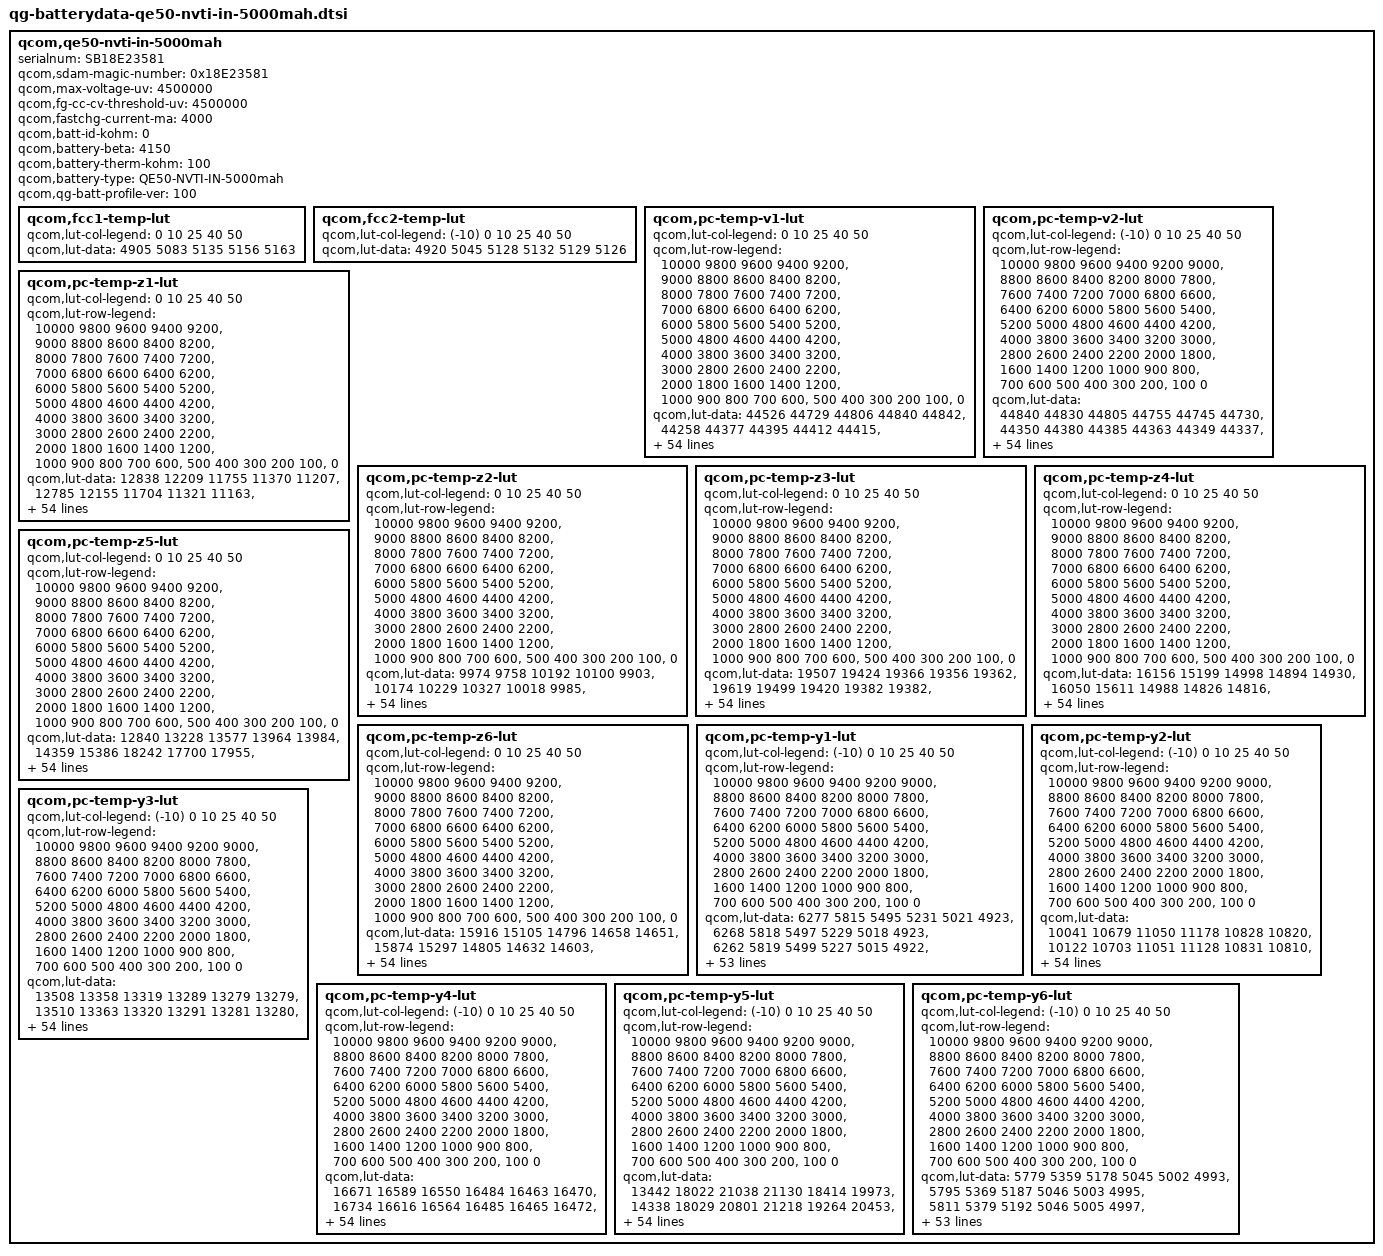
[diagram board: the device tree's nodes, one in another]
/* Copyright (c) 2018, The Linux Foundation. All rights reserved.
 *
 * This program is free software; you can redistribute it and/or modify
 * it under the terms of the GNU General Public License version 2 and
 * only version 2 as published by the Free Software Foundation.
 *
 * This program is distributed in the hope that it will be useful,
 * but WITHOUT ANY WARRANTY; without even the implied warranty of
 * MERCHANTABILITY or FITNESS FOR A PARTICULAR PURPOSE.  See the
 * GNU General Public License for more details.
 */

qcom,qe50-nvti-in-5000mah {
    /* 7091166_Huaqin_QN6982A_5000mAH_PM7250B_averaged_MasterSlave_Apr16th2024 */
    serialnum = "SB18E23581";
    qcom,sdam-magic-number = <0x18E23581>;
    qcom,max-voltage-uv = <4500000>;
    qcom,fg-cc-cv-threshold-uv = <4500000>;
    qcom,fastchg-current-ma = <4000>;
    qcom,batt-id-kohm = <0>;
    qcom,battery-beta = <4150>;
    qcom,battery-therm-kohm = <100>;
    qcom,battery-type = "QE50-NVTI-IN-5000mah";
    qcom,qg-batt-profile-ver = <100>;

	qcom,fcc1-temp-lut {
		qcom,lut-col-legend = <0 10 25 40 50>;
		qcom,lut-data = <4905 5083 5135 5156 5163>;
	};

	qcom,fcc2-temp-lut {
		qcom,lut-col-legend = <(-10) 0 10 25 40 50>;
		qcom,lut-data = <4920 5045 5128 5132 5129 5126>;
	};

	qcom,pc-temp-v1-lut {
		qcom,lut-col-legend = <0 10 25 40 50>;
		qcom,lut-row-legend = <10000 9800 9600 9400 9200>,
			<9000 8800 8600 8400 8200>,
			<8000 7800 7600 7400 7200>,
			<7000 6800 6600 6400 6200>,
			<6000 5800 5600 5400 5200>,
			<5000 4800 4600 4400 4200>,
			<4000 3800 3600 3400 3200>,
			<3000 2800 2600 2400 2200>,
			<2000 1800 1600 1400 1200>,
			<1000 900 800 700 600>,
			<500 400 300 200 100>,
			<0>;
		qcom,lut-data = <44526 44729 44806 44840 44842>,
			<44258 44377 44395 44412 44415>,
			<44018 44137 44140 44133 44132>,
			<43808 43932 43925 43917 43909>,
			<43598 43711 43709 43707 43695>,
			<43373 43489 43489 43487 43478>,
			<43140 43260 43265 43262 43260>,
			<42902 43019 43030 43029 43030>,
			<42657 42772 42785 42787 42789>,
			<42412 42524 42538 42542 42545>,
			<42173 42273 42288 42295 42297>,
			<41938 42028 42040 42049 42050>,
			<41707 41785 41797 41807 41808>,
			<41480 41548 41558 41569 41569>,
			<41260 41321 41327 41337 41337>,
			<41047 41101 41102 41111 41110>,
			<40842 40889 40886 40891 40888>,
			<40644 40683 40678 40682 40677>,
			<40454 40487 40481 40481 40474>,
			<40271 40303 40296 40294 40285>,
			<40095 40127 40126 40126 40115>,
			<39926 39938 39938 39936 39927>,
			<39753 39740 39710 39665 39664>,
			<39563 39530 39476 39385 39389>,
			<39367 39274 39264 39199 39206>,
			<39168 39027 39067 39059 39070>,
			<38952 38885 38921 38933 38943>,
			<38784 38795 38818 38817 38815>,
			<38690 38712 38727 38710 38699>,
			<38620 38623 38631 38608 38598>,
			<38555 38539 38539 38514 38509>,
			<38493 38461 38455 38430 38427>,
			<38436 38388 38377 38356 38351>,
			<38382 38322 38306 38287 38278>,
			<38332 38266 38244 38220 38207>,
			<38287 38214 38187 38155 38137>,
			<38250 38170 38130 38088 38066>,
			<38211 38131 38075 38023 37996>,
			<38164 38079 38008 37944 37911>,
			<38108 38002 37923 37839 37790>,
			<38034 37906 37822 37718 37652>,
			<37919 37789 37708 37602 37528>,
			<37783 37645 37572 37481 37404>,
			<37632 37477 37407 37317 37235>,
			<37473 37307 37243 37166 37087>,
			<37290 37174 37127 37072 37007>,
			<37222 37128 37085 37038 36981>,
			<37171 37093 37056 37014 36958>,
			<37134 37070 37030 36989 36932>,
			<37096 37036 36994 36951 36886>,
			<37051 36911 36835 36753 36664>,
			<36980 36513 36414 36335 36245>,
			<36715 35913 35829 35762 35671>,
			<36163 35068 35026 34976 34885>,
			<35205 33680 33776 33761 33666>,
			<30000 30000 30000 30000 30000>;
	};

	qcom,pc-temp-v2-lut {
		qcom,lut-col-legend = <(-10) 0 10 25 40 50>;
		qcom,lut-row-legend = <10000 9800 9600 9400 9200 9000>,
			<8800 8600 8400 8200 8000 7800>,
			<7600 7400 7200 7000 6800 6600>,
			<6400 6200 6000 5800 5600 5400>,
			<5200 5000 4800 4600 4400 4200>,
			<4000 3800 3600 3400 3200 3000>,
			<2800 2600 2400 2200 2000 1800>,
			<1600 1400 1200 1000 900 800>,
			<700 600 500 400 300 200>,
			<100 0>;
		qcom,lut-data = <44840 44830 44805 44755 44745 44730>,
			<44350 44380 44385 44363 44349 44337>,
			<43941 44005 44031 44028 44011 44001>,
			<43639 43725 43760 43764 43746 43736>,
			<43416 43516 43551 43553 43537 43525>,
			<43206 43310 43340 43341 43325 43314>,
			<42974 43083 43110 43111 43096 43085>,
			<42738 42851 42874 42874 42861 42851>,
			<42502 42612 42630 42632 42619 42612>,
			<42263 42364 42379 42384 42371 42366>,
			<42026 42117 42130 42136 42123 42121>,
			<41796 41871 41883 41890 41876 41876>,
			<41570 41627 41639 41646 41632 41633>,
			<41345 41393 41399 41407 41396 41396>,
			<41127 41167 41164 41174 41166 41163>,
			<40902 40953 40937 40948 40942 40938>,
			<40650 40761 40718 40729 40722 40719>,
			<40379 40566 40509 40519 40511 40509>,
			<40113 40333 40323 40320 40313 40308>,
			<39853 40064 40140 40127 40123 40114>,
			<39604 39803 39917 39934 39940 39933>,
			<39374 39552 39641 39741 39770 39769>,
			<39161 39317 39381 39532 39577 39583>,
			<38959 39111 39155 39269 39310 39319>,
			<38753 38925 38952 39010 39038 39047>,
			<38567 38757 38782 38830 38855 38865>,
			<38428 38605 38635 38691 38717 38729>,
			<38316 38465 38502 38569 38595 38607>,
			<38224 38329 38381 38457 38482 38489>,
			<38146 38198 38271 38355 38379 38382>,
			<38078 38096 38171 38259 38288 38288>,
			<38012 38017 38079 38169 38205 38203>,
			<37950 37949 37998 38089 38128 38127>,
			<37888 37890 37926 38018 38060 38063>,
			<37827 37839 37861 37948 37991 37995>,
			<37766 37786 37806 37875 37914 37908>,
			<37702 37729 37757 37801 37830 37808>,
			<37636 37669 37699 37721 37736 37702>,
			<37566 37602 37635 37634 37626 37588>,
			<37492 37528 37558 37543 37516 37476>,
			<37414 37440 37456 37448 37422 37380>,
			<37327 37330 37333 37344 37324 37281>,
			<37228 37206 37188 37222 37216 37171>,
			<37123 37064 37021 37079 37063 37011>,
			<37012 36903 36841 36935 36930 36882>,
			<36917 36761 36721 36861 36869 36820>,
			<36869 36705 36678 36845 36857 36807>,
			<36822 36659 36635 36829 36843 36793>,
			<36776 36619 36576 36803 36820 36769>,
			<36726 36569 36482 36738 36765 36710>,
			<36663 36476 36254 36510 36551 36475>,
			<36582 36281 35728 36017 36073 35983>,
			<36481 35866 34900 35343 35433 35336>,
			<36172 35055 33898 34407 34534 34428>,
			<35860 34221 32625 32974 33234 33115>,
			<35541 33188 28873 28521 28685 28727>;
	};

	qcom,pc-temp-z1-lut {
		qcom,lut-col-legend = <0 10 25 40 50>;
		qcom,lut-row-legend = <10000 9800 9600 9400 9200>,
			<9000 8800 8600 8400 8200>,
			<8000 7800 7600 7400 7200>,
			<7000 6800 6600 6400 6200>,
			<6000 5800 5600 5400 5200>,
			<5000 4800 4600 4400 4200>,
			<4000 3800 3600 3400 3200>,
			<3000 2800 2600 2400 2200>,
			<2000 1800 1600 1400 1200>,
			<1000 900 800 700 600>,
			<500 400 300 200 100>,
			<0>;
		qcom,lut-data = <12838 12209 11755 11370 11207>,
			<12785 12155 11704 11321 11163>,
			<12758 12145 11674 11306 11152>,
			<12748 12139 11661 11294 11144>,
			<12742 12124 11647 11283 11137>,
			<12733 12099 11628 11274 11130>,
			<12719 12076 11611 11265 11124>,
			<12707 12055 11600 11257 11119>,
			<12689 12037 11592 11250 11116>,
			<12666 12022 11584 11245 11113>,
			<12638 12006 11578 11242 11112>,
			<12602 11998 11572 11240 11110>,
			<12573 11987 11567 11239 11109>,
			<12549 11979 11562 11238 11108>,
			<12530 11976 11561 11237 11107>,
			<12515 11971 11561 11236 11107>,
			<12504 11970 11561 11235 11106>,
			<12496 11971 11560 11235 11107>,
			<12489 11972 11560 11236 11108>,
			<12484 11971 11562 11236 11108>,
			<12489 11969 11566 11236 11108>,
			<12511 11969 11569 11236 11108>,
			<12529 11969 11568 11237 11108>,
			<12538 11970 11567 11237 11109>,
			<12545 11980 11569 11238 11110>,
			<12545 11995 11575 11240 11111>,
			<12534 12001 11579 11243 11114>,
			<12525 12003 11582 11246 11115>,
			<12528 12006 11586 11250 11117>,
			<12538 12011 11591 11253 11120>,
			<12543 12015 11599 11256 11122>,
			<12555 12017 11602 11260 11125>,
			<12565 12016 11604 11263 11127>,
			<12567 12017 11607 11267 11130>,
			<12572 12024 11614 11272 11134>,
			<12575 12033 11623 11277 11139>,
			<12577 12041 11630 11283 11143>,
			<12580 12050 11636 11288 11147>,
			<12595 12060 11644 11293 11151>,
			<12628 12072 11656 11299 11156>,
			<12649 12083 11667 11304 11161>,
			<12668 12086 11673 11310 11165>,
			<12680 12090 11679 11315 11168>,
			<12708 12109 11685 11320 11171>,
			<12713 12136 11698 11326 11175>,
			<12749 12133 11709 11329 11177>,
			<12767 12130 11708 11329 11178>,
			<12752 12156 11711 11330 11179>,
			<12730 12128 11715 11334 11182>,
			<12778 12145 11719 11339 11187>,
			<12745 12153 11741 11347 11192>,
			<12769 12183 11749 11357 11202>,
			<12781 12192 11773 11372 11215>,
			<12801 12227 11798 11395 11238>,
			<12801 12227 11798 11395 11238>,
			<12801 12227 11798 11395 11238>;
	};

	qcom,pc-temp-z2-lut {
		qcom,lut-col-legend = <0 10 25 40 50>;
		qcom,lut-row-legend = <10000 9800 9600 9400 9200>,
			<9000 8800 8600 8400 8200>,
			<8000 7800 7600 7400 7200>,
			<7000 6800 6600 6400 6200>,
			<6000 5800 5600 5400 5200>,
			<5000 4800 4600 4400 4200>,
			<4000 3800 3600 3400 3200>,
			<3000 2800 2600 2400 2200>,
			<2000 1800 1600 1400 1200>,
			<1000 900 800 700 600>,
			<500 400 300 200 100>,
			<0>;
		qcom,lut-data = <9974 9758 10192 10100 9903>,
			<10174 10229 10327 10018 9985>,
			<10222 10287 10358 10182 10024>,
			<10208 10337 10345 10176 10136>,
			<10189 10330 10339 10170 10215>,
			<10170 10289 10340 10167 10199>,
			<10148 10258 10340 10163 10165>,
			<10130 10240 10304 10155 10140>,
			<10116 10226 10220 10139 10119>,
			<10103 10212 10193 10122 10101>,
			<10093 10198 10193 10093 10087>,
			<10083 10196 10194 10064 10074>,
			<10080 10210 10198 10058 10053>,
			<10082 10224 10204 10060 10026>,
			<10085 10229 10206 10065 10019>,
			<10093 10233 10205 10075 10037>,
			<10110 10239 10205 10081 10054>,
			<10128 10249 10217 10075 10051>,
			<10142 10262 10230 10064 10040>,
			<10156 10273 10230 10062 10040>,
			<10171 10285 10223 10070 10046>,
			<10186 10302 10223 10084 10058>,
			<10202 10330 10281 10292 10209>,
			<10225 10347 10343 10551 10411>,
			<10249 10348 10319 10496 10386>,
			<10261 10346 10246 10218 10198>,
			<10269 10337 10222 10107 10124>,
			<10273 10315 10237 10253 10370>,
			<10274 10303 10253 10397 10624>,
			<10275 10305 10260 10365 10531>,
			<10276 10307 10265 10258 10245>,
			<10280 10308 10267 10171 10081>,
			<10284 10312 10267 10094 9996>,
			<10289 10317 10266 10048 9957>,
			<10295 10331 10257 10038 9962>,
			<10302 10346 10247 10035 9977>,
			<10311 10354 10251 10047 9999>,
			<10318 10358 10277 10086 10042>,
			<10321 10366 10302 10122 10087>,
			<10325 10382 10324 10146 10136>,
			<10326 10395 10340 10165 10176>,
			<10326 10391 10342 10181 10185>,
			<10327 10382 10342 10195 10185>,
			<10337 10382 10337 10198 10182>,
			<10291 10412 10344 10201 10177>,
			<10474 10464 10354 10194 10158>,
			<10463 10457 10350 10195 10147>,
			<10402 10456 10325 10190 10146>,
			<10203 10670 10326 10203 10153>,
			<10016 10860 10348 10252 10212>,
			<10068 10873 10356 10223 10181>,
			<10048 10534 10340 10146 10044>,
			<9939 10376 10312 10087 10000>,
			<9828 10286 10269 10054 9963>,
			<9828 10286 10269 10054 9963>,
			<9828 10286 10269 10054 9963>;
	};

	qcom,pc-temp-z3-lut {
		qcom,lut-col-legend = <0 10 25 40 50>;
		qcom,lut-row-legend = <10000 9800 9600 9400 9200>,
			<9000 8800 8600 8400 8200>,
			<8000 7800 7600 7400 7200>,
			<7000 6800 6600 6400 6200>,
			<6000 5800 5600 5400 5200>,
			<5000 4800 4600 4400 4200>,
			<4000 3800 3600 3400 3200>,
			<3000 2800 2600 2400 2200>,
			<2000 1800 1600 1400 1200>,
			<1000 900 800 700 600>,
			<500 400 300 200 100>,
			<0>;
		qcom,lut-data = <19507 19424 19366 19356 19362>,
			<19619 19499 19420 19382 19382>,
			<19661 19518 19436 19407 19402>,
			<19673 19527 19442 19407 19406>,
			<19678 19531 19443 19408 19408>,
			<19678 19534 19441 19413 19410>,
			<19677 19535 19440 19419 19412>,
			<19675 19533 19440 19420 19412>,
			<19673 19529 19440 19418 19411>,
			<19669 19526 19440 19416 19409>,
			<19663 19523 19437 19413 19408>,
			<19653 19519 19434 19409 19405>,
			<19645 19513 19431 19405 19403>,
			<19639 19507 19428 19401 19399>,
			<19632 19501 19426 19398 19396>,
			<19625 19495 19424 19396 19393>,
			<19616 19491 19422 19394 19391>,
			<19608 19489 19419 19391 19387>,
			<19602 19487 19415 19388 19384>,
			<19597 19483 19412 19384 19380>,
			<19592 19480 19407 19378 19374>,
			<19586 19480 19406 19375 19370>,
			<19584 19484 19413 19385 19375>,
			<19587 19487 19421 19397 19382>,
			<19594 19489 19418 19393 19378>,
			<19597 19490 19409 19373 19362>,
			<19599 19489 19406 19365 19356>,
			<19599 19484 19407 19390 19390>,
			<19597 19482 19410 19414 19427>,
			<19591 19483 19415 19416 19426>,
			<19586 19484 19423 19415 19416>,
			<19583 19486 19424 19412 19407>,
			<19580 19488 19423 19404 19399>,
			<19579 19488 19422 19395 19390>,
			<19577 19487 19418 19387 19382>,
			<19576 19485 19414 19380 19373>,
			<19574 19482 19410 19373 19364>,
			<19571 19478 19406 19367 19354>,
			<19567 19474 19403 19364 19350>,
			<19561 19470 19401 19366 19352>,
			<19555 19466 19399 19368 19355>,
			<19551 19463 19395 19367 19357>,
			<19545 19460 19391 19365 19360>,
			<19536 19457 19390 19366 19362>,
			<19425 19447 19387 19365 19361>,
			<19482 19428 19378 19358 19355>,
			<19475 19427 19377 19356 19352>,
			<19423 19424 19371 19346 19341>,
			<19315 19349 19366 19344 19334>,
			<19269 19321 19365 19334 19325>,
			<19268 19319 19366 19347 19332>,
			<19265 19377 19378 19359 19349>,
			<19271 19429 19381 19360 19350>,
			<19336 19447 19382 19362 19352>,
			<19336 19447 19382 19362 19352>,
			<19336 19447 19382 19362 19352>;
	};

	qcom,pc-temp-z4-lut {
		qcom,lut-col-legend = <0 10 25 40 50>;
		qcom,lut-row-legend = <10000 9800 9600 9400 9200>,
			<9000 8800 8600 8400 8200>,
			<8000 7800 7600 7400 7200>,
			<7000 6800 6600 6400 6200>,
			<6000 5800 5600 5400 5200>,
			<5000 4800 4600 4400 4200>,
			<4000 3800 3600 3400 3200>,
			<3000 2800 2600 2400 2200>,
			<2000 1800 1600 1400 1200>,
			<1000 900 800 700 600>,
			<500 400 300 200 100>,
			<0>;
		qcom,lut-data = <16156 15199 14998 14894 14930>,
			<16050 15611 14988 14826 14816>,
			<15891 15434 15074 14924 14904>,
			<15644 15185 14966 14871 14858>,
			<15412 15060 14883 14819 14812>,
			<15267 14975 14838 14792 14789>,
			<15154 14912 14804 14770 14771>,
			<15066 14864 14778 14750 14755>,
			<14993 14825 14757 14732 14741>,
			<14935 14795 14741 14723 14734>,
			<14889 14770 14726 14720 14732>,
			<14852 14751 14716 14718 14731>,
			<14821 14736 14710 14715 14729>,
			<14794 14725 14706 14711 14726>,
			<14772 14721 14703 14708 14724>,
			<14757 14718 14699 14704 14721>,
			<14744 14715 14696 14700 14718>,
			<14737 14711 14694 14697 14715>,
			<14733 14708 14691 14694 14713>,
			<14730 14704 14688 14689 14708>,
			<14728 14700 14684 14680 14697>,
			<14725 14700 14683 14675 14690>,
			<14724 14708 14704 14712 14728>,
			<14730 14721 14736 14768 14786>,
			<14745 14767 14769 14794 14807>,
			<14767 14821 14805 14811 14818>,
			<14812 14825 14813 14814 14820>,
			<14841 14804 14793 14774 14769>,
			<14836 14783 14768 14728 14715>,
			<14821 14766 14748 14714 14708>,
			<14808 14752 14729 14706 14706>,
			<14797 14741 14717 14700 14702>,
			<14787 14732 14710 14695 14697>,
			<14778 14727 14704 14690 14691>,
			<14770 14725 14700 14685 14685>,
			<14762 14722 14697 14679 14679>,
			<14755 14719 14694 14675 14675>,
			<14746 14715 14692 14672 14671>,
			<14735 14710 14691 14671 14670>,
			<14721 14705 14691 14680 14684>,
			<14711 14699 14692 14691 14700>,
			<14704 14691 14689 14689 14698>,
			<14696 14681 14680 14681 14689>,
			<14681 14671 14674 14684 14696>,
			<14749 14657 14663 14681 14697>,
			<14668 14645 14644 14654 14662>,
			<14676 14640 14640 14648 14652>,
			<14735 14637 14635 14643 14645>,
			<14852 14713 14627 14628 14631>,
			<14898 14740 14618 14618 14618>,
			<14895 14741 14623 14635 14654>,
			<14892 14688 14633 14658 14682>,
			<14896 14643 14637 14668 14693>,
			<14865 14654 14644 14674 14699>,
			<14865 14654 14644 14674 14699>,
			<14865 14654 14644 14674 14699>;
	};

	qcom,pc-temp-z5-lut {
		qcom,lut-col-legend = <0 10 25 40 50>;
		qcom,lut-row-legend = <10000 9800 9600 9400 9200>,
			<9000 8800 8600 8400 8200>,
			<8000 7800 7600 7400 7200>,
			<7000 6800 6600 6400 6200>,
			<6000 5800 5600 5400 5200>,
			<5000 4800 4600 4400 4200>,
			<4000 3800 3600 3400 3200>,
			<3000 2800 2600 2400 2200>,
			<2000 1800 1600 1400 1200>,
			<1000 900 800 700 600>,
			<500 400 300 200 100>,
			<0>;
		qcom,lut-data = <12840 13228 13577 13964 13984>,
			<14359 15386 18242 17700 17955>,
			<15337 16539 17492 18467 18336>,
			<15929 17364 18799 19482 20648>,
			<16465 18325 19954 20709 23030>,
			<17100 19300 20761 22178 24186>,
			<17784 20235 21497 23793 25124>,
			<18590 21088 22175 25332 26291>,
			<19605 21965 22814 26896 27695>,
			<20678 23000 23655 27720 28687>,
			<21620 24176 24939 27964 29255>,
			<22514 25442 26142 28030 29640>,
			<23610 27111 26885 28083 29868>,
			<25169 28190 27497 28357 30058>,
			<26898 28242 28265 28851 30377>,
			<28493 28252 29244 30015 31403>,
			<30028 28418 30028 31286 32640>,
			<31087 29530 30763 32367 33654>,
			<31845 30837 31362 33292 34688>,
			<32566 31655 31369 33562 35703>,
			<33292 32495 31286 33578 36968>,
			<34129 34586 31671 33717 38321>,
			<35455 39886 36171 40852 41082>,
			<41519 42976 40777 50033 44080>,
			<49840 41722 37662 45637 40439>,
			<51950 39079 28538 27478 25627>,
			<51886 35865 24505 19935 19276>,
			<51415 31293 23479 23032 27938>,
			<48253 29228 23036 27286 36960>,
			<42656 29808 24483 30496 37100>,
			<39782 31012 27963 33374 36043>,
			<38344 32888 31032 33979 35242>,
			<37637 36058 34030 33357 34718>,
			<37926 38851 36349 32848 34142>,
			<38757 41308 37795 32782 33327>,
			<39522 43035 38909 32754 32341>,
			<40208 43451 39910 32825 31234>,
			<40865 43603 40898 33218 29862>,
			<41566 43584 41260 33936 29278>,
			<42396 43423 41117 37758 32689>,
			<42841 43173 40798 41945 36942>,
			<43110 42614 38937 40155 36901>,
			<42741 41968 35607 35020 35763>,
			<39249 42093 36626 37383 38519>,
			<27139 42471 39645 39717 41142>,
			<30979 36478 37548 36434 38592>,
			<28319 36207 35957 32080 32518>,
			<21180 33634 31167 25437 24021>,
			<12244 15029 30295 29978 25429>,
			<11271 12791 33920 28284 28204>,
			<11245 12733 32590 42582 32483>,
			<11228 21922 36750 28539 22632>,
			<11277 32420 34201 22673 18417>,
			<12569 39842 29681 19582 16219>,
			<12569 39842 29681 19582 16219>,
			<12569 39842 29681 19582 16219>;
	};

	qcom,pc-temp-z6-lut {
		qcom,lut-col-legend = <0 10 25 40 50>;
		qcom,lut-row-legend = <10000 9800 9600 9400 9200>,
			<9000 8800 8600 8400 8200>,
			<8000 7800 7600 7400 7200>,
			<7000 6800 6600 6400 6200>,
			<6000 5800 5600 5400 5200>,
			<5000 4800 4600 4400 4200>,
			<4000 3800 3600 3400 3200>,
			<3000 2800 2600 2400 2200>,
			<2000 1800 1600 1400 1200>,
			<1000 900 800 700 600>,
			<500 400 300 200 100>,
			<0>;
		qcom,lut-data = <15916 15105 14796 14658 14651>,
			<15874 15297 14805 14632 14603>,
			<15800 15214 14844 14685 14648>,
			<15666 15094 14794 14659 14629>,
			<15531 15028 14755 14636 14609>,
			<15441 14980 14731 14626 14600>,
			<15367 14941 14713 14618 14592>,
			<15305 14908 14697 14609 14585>,
			<15253 14880 14684 14599 14578>,
			<15208 14856 14673 14593 14573>,
			<15168 14836 14664 14589 14571>,
			<15133 14820 14657 14586 14569>,
			<15103 14807 14652 14582 14566>,
			<15077 14796 14648 14578 14563>,
			<15054 14789 14644 14574 14560>,
			<15037 14784 14641 14571 14557>,
			<15023 14780 14638 14568 14553>,
			<15015 14777 14636 14565 14551>,
			<15011 14774 14633 14562 14547>,
			<15008 14770 14630 14557 14543>,
			<15006 14767 14626 14550 14534>,
			<15003 14767 14625 14546 14530>,
			<15003 14773 14638 14570 14550>,
			<15008 14781 14656 14601 14579>,
			<15020 14804 14669 14605 14583>,
			<15034 14829 14681 14604 14581>,
			<15056 14830 14684 14602 14579>,
			<15070 14820 14677 14598 14577>,
			<15067 14811 14669 14593 14575>,
			<15059 14806 14665 14589 14571>,
			<15053 14803 14662 14586 14565>,
			<15049 14801 14659 14581 14559>,
			<15045 14799 14656 14576 14553>,
			<15043 14799 14654 14570 14546>,
			<15041 14799 14651 14564 14539>,
			<15040 14799 14649 14558 14533>,
			<15041 14798 14647 14554 14526>,
			<15041 14797 14646 14549 14520>,
			<15041 14797 14646 14548 14517>,
			<15041 14796 14647 14553 14524>,
			<15041 14796 14648 14559 14533>,
			<15045 14796 14646 14559 14533>,
			<15050 14795 14643 14555 14531>,
			<15054 14795 14643 14558 14535>,
			<15048 14793 14640 14556 14536>,
			<15051 14785 14630 14542 14518>,
			<15052 14783 14628 14539 14513>,
			<15052 14780 14624 14532 14505>,
			<15049 14776 14619 14524 14495>,
			<15049 14777 14617 14516 14485>,
			<15050 14783 14623 14530 14505>,
			<15058 14797 14638 14550 14529>,
			<15075 14814 14647 14558 14538>,
			<15106 14841 14658 14566 14546>,
			<15106 14841 14658 14566 14546>,
			<15106 14841 14658 14566 14546>;
	};

	qcom,pc-temp-y1-lut {
		qcom,lut-col-legend = <(-10) 0 10 25 40 50>;
		qcom,lut-row-legend = <10000 9800 9600 9400 9200 9000>,
			<8800 8600 8400 8200 8000 7800>,
			<7600 7400 7200 7000 6800 6600>,
			<6400 6200 6000 5800 5600 5400>,
			<5200 5000 4800 4600 4400 4200>,
			<4000 3800 3600 3400 3200 3000>,
			<2800 2600 2400 2200 2000 1800>,
			<1600 1400 1200 1000 900 800>,
			<700 600 500 400 300 200>,
			<100 0>;
		qcom,lut-data = <6277 5815 5495 5231 5021 4923>,
			<6268 5818 5497 5229 5018 4923>,
			<6262 5819 5499 5227 5015 4922>,
			<6259 5819 5502 5225 5012 4921>,
			<6258 5819 5503 5223 5010 4921>,
			<6258 5818 5504 5221 5007 4920>,
			<6263 5804 5506 5217 5004 4920>,
			<6273 5786 5506 5213 5002 4919>,
			<6276 5788 5505 5209 4999 4918>,
			<6269 5807 5502 5205 4997 4915>,
			<6263 5818 5500 5203 4995 4914>,
			<6268 5815 5498 5201 4994 4913>,
			<6279 5811 5496 5199 4992 4912>,
			<6287 5811 5491 5197 4990 4912>,
			<6292 5815 5482 5195 4988 4911>,
			<6295 5818 5480 5194 4987 4910>,
			<6297 5815 5484 5193 4987 4910>,
			<6302 5811 5487 5193 4987 4909>,
			<6300 5811 5484 5193 4987 4909>,
			<6284 5813 5481 5193 4988 4909>,
			<6269 5814 5480 5195 4989 4910>,
			<6268 5816 5481 5197 4990 4911>,
			<6269 5818 5483 5199 4991 4912>,
			<6272 5818 5484 5201 4992 4912>,
			<6284 5817 5485 5203 4994 4913>,
			<6296 5815 5488 5204 4996 4914>,
			<6295 5808 5495 5205 4997 4915>,
			<6285 5802 5498 5208 4999 4916>,
			<6279 5802 5493 5212 5000 4918>,
			<6282 5803 5489 5217 5001 4919>,
			<6288 5805 5491 5221 5004 4921>,
			<6288 5809 5498 5226 5007 4923>,
			<6286 5814 5505 5229 5009 4924>,
			<6290 5823 5512 5231 5011 4926>,
			<6301 5835 5517 5233 5013 4928>,
			<6313 5837 5517 5237 5014 4929>,
			<6313 5823 5515 5242 5016 4930>,
			<6293 5812 5514 5244 5017 4931>,
			<6276 5815 5514 5245 5017 4932>,
			<6284 5823 5514 5246 5017 4933>,
			<6303 5829 5521 5263 5019 4934>,
			<6310 5837 5526 5279 5021 4935>,
			<6310 5836 5525 5261 5022 4936>,
			<6305 5835 5529 5259 5025 4938>,
			<6278 5836 5537 5264 5030 4941>,
			<6298 5850 5546 5270 5033 4945>,
			<6306 5846 5535 5276 5033 4943>,
			<6311 5855 5550 5275 5033 4944>,
			<6337 5864 5545 5274 5033 4945>,
			<6406 5875 5548 5274 5032 4947>,
			<6487 5919 5581 5280 5035 4947>,
			<6502 5976 5618 5286 5041 4951>,
			<6547 5905 5641 5307 5048 4960>,
			<6406 5494 5515 5336 5060 4971>,
			<6406 5494 5515 5336 5060 4971>,
			<6406 5494 5515 5336 5060 4971>;
	};

	qcom,pc-temp-y2-lut {
		qcom,lut-col-legend = <(-10) 0 10 25 40 50>;
		qcom,lut-row-legend = <10000 9800 9600 9400 9200 9000>,
			<8800 8600 8400 8200 8000 7800>,
			<7600 7400 7200 7000 6800 6600>,
			<6400 6200 6000 5800 5600 5400>,
			<5200 5000 4800 4600 4400 4200>,
			<4000 3800 3600 3400 3200 3000>,
			<2800 2600 2400 2200 2000 1800>,
			<1600 1400 1200 1000 900 800>,
			<700 600 500 400 300 200>,
			<100 0>;
		qcom,lut-data = <10041 10679 11050 11178 10828 10820>,
			<10122 10703 11051 11128 10831 10810>,
			<10216 10729 11042 11067 10828 10797>,
			<10310 10752 11028 11006 10821 10781>,
			<10389 10769 11008 10956 10812 10764>,
			<10440 10775 10984 10929 10804 10747>,
			<10462 10771 10954 10920 10785 10725>,
			<10477 10764 10921 10912 10762 10706>,
			<10494 10759 10891 10888 10747 10701>,
			<10514 10754 10863 10848 10733 10698>,
			<10538 10752 10850 10825 10718 10690>,
			<10573 10763 10846 10816 10702 10660>,
			<10617 10785 10843 10809 10688 10632>,
			<10661 10808 10853 10797 10670 10626>,
			<10713 10838 10880 10784 10644 10624>,
			<10749 10876 10911 10784 10637 10622>,
			<10754 10948 10949 10807 10644 10610>,
			<10756 11013 10996 10840 10654 10600>,
			<10749 11023 11071 10881 10682 10599>,
			<10547 11022 11148 10937 10733 10603>,
			<10305 11017 11159 11004 10806 10645>,
			<10159 11000 11141 11095 10929 10812>,
			<9862 10984 11123 11137 10990 10909>,
			<9719 10982 11109 11085 10935 10879>,
			<9704 10985 11098 11017 10861 10835>,
			<9695 10986 11103 11007 10849 10824>,
			<9689 10984 11125 11012 10853 10829>,
			<9685 10981 11138 11024 10861 10840>,
			<9682 10969 11142 11070 10884 10877>,
			<9679 10941 11145 11113 10911 10916>,
			<9677 10913 11143 11116 10927 10928>,
			<9675 10880 11138 11114 10941 10940>,
			<9673 10841 11137 11114 10951 10947>,
			<9671 10741 11146 11123 10965 10970>,
			<9669 10563 11153 11130 10979 10987>,
			<9668 10410 11133 11123 10986 10974>,
			<9667 10118 11082 11110 10986 10948>,
			<9666 9849 11035 11108 10980 10928>,
			<9665 9768 10989 11115 10964 10908>,
			<9665 9720 10930 11120 10944 10898>,
			<9664 9698 10833 11108 10915 10900>,
			<9663 9686 10711 11099 10897 10902>,
			<9662 9677 10588 11085 10921 10898>,
			<9661 9671 10289 11078 10921 10872>,
			<9660 9666 9942 11042 10921 10784>,
			<9658 9663 9820 10972 10799 10673>,
			<9657 9660 9730 10979 10802 10658>,
			<9655 9658 9687 10995 10804 10660>,
			<9653 9655 9669 10980 10811 10656>,
			<9650 9652 9659 11024 10810 10708>,
			<9649 9649 9654 10986 10770 10684>,
			<9648 9648 9651 10844 10731 10603>,
			<9648 9649 9650 10759 10658 10526>,
			<9648 9650 9650 10667 10534 10394>,
			<9648 9650 9650 10667 10534 10394>,
			<9648 9650 9650 10667 10534 10394>;
	};

	qcom,pc-temp-y3-lut {
		qcom,lut-col-legend = <(-10) 0 10 25 40 50>;
		qcom,lut-row-legend = <10000 9800 9600 9400 9200 9000>,
			<8800 8600 8400 8200 8000 7800>,
			<7600 7400 7200 7000 6800 6600>,
			<6400 6200 6000 5800 5600 5400>,
			<5200 5000 4800 4600 4400 4200>,
			<4000 3800 3600 3400 3200 3000>,
			<2800 2600 2400 2200 2000 1800>,
			<1600 1400 1200 1000 900 800>,
			<700 600 500 400 300 200>,
			<100 0>;
		qcom,lut-data = <13508 13358 13319 13289 13279 13279>,
			<13510 13363 13320 13291 13281 13280>,
			<13511 13368 13322 13292 13283 13281>,
			<13511 13372 13324 13293 13284 13282>,
			<13510 13376 13326 13294 13286 13283>,
			<13508 13379 13328 13295 13287 13284>,
			<13506 13382 13329 13296 13287 13284>,
			<13504 13384 13331 13296 13288 13285>,
			<13501 13386 13332 13297 13288 13286>,
			<13496 13386 13332 13298 13289 13286>,
			<13492 13387 13333 13298 13289 13287>,
			<13487 13385 13335 13299 13289 13288>,
			<13483 13382 13336 13299 13290 13288>,
			<13477 13378 13336 13299 13291 13289>,
			<13472 13373 13335 13300 13292 13290>,
			<13465 13370 13334 13301 13293 13290>,
			<13457 13371 13330 13302 13293 13291>,
			<13446 13372 13327 13303 13293 13292>,
			<13437 13370 13327 13302 13294 13292>,
			<13428 13364 13328 13301 13296 13292>,
			<13421 13358 13327 13301 13297 13292>,
			<13423 13352 13322 13301 13295 13292>,
			<13429 13347 13317 13302 13292 13292>,
			<13431 13343 13314 13298 13288 13288>,
			<13427 13340 13312 13293 13285 13282>,
			<13422 13337 13311 13291 13283 13282>,
			<13422 13334 13309 13291 13283 13282>,
			<13426 13331 13308 13290 13282 13282>,
			<13432 13328 13307 13291 13282 13281>,
			<13443 13326 13306 13291 13281 13279>,
			<13461 13325 13305 13290 13281 13279>,
			<13483 13323 13304 13289 13281 13279>,
			<13511 13322 13304 13289 13281 13280>,
			<13544 13322 13304 13289 13282 13281>,
			<13582 13324 13304 13289 13282 13282>,
			<13626 13328 13304 13289 13283 13282>,
			<13673 13336 13305 13289 13283 13282>,
			<13725 13348 13306 13288 13283 13282>,
			<13781 13364 13308 13288 13282 13281>,
			<13842 13385 13311 13288 13282 13281>,
			<13909 13408 13313 13288 13283 13282>,
			<13980 13433 13317 13288 13283 13283>,
			<14057 13470 13322 13288 13283 13282>,
			<14148 13531 13328 13288 13281 13279>,
			<14260 13629 13322 13286 13280 13280>,
			<14440 13767 13351 13288 13284 13284>,
			<14551 13920 13384 13291 13287 13286>,
			<14748 14160 13440 13294 13289 13288>,
			<15297 14596 13568 13297 13291 13290>,
			<16590 15840 13929 13298 13291 13291>,
			<19532 19821 15032 13297 13288 13289>,
			<26854 33734 19162 13296 13287 13290>,
			<47317 65535 36433 13303 13291 13292>,
			<65535 65535 65535 13316 13298 13300>,
			<65535 65535 65535 13316 13298 13300>,
			<65535 65535 65535 13316 13298 13300>;
	};

	qcom,pc-temp-y4-lut {
		qcom,lut-col-legend = <(-10) 0 10 25 40 50>;
		qcom,lut-row-legend = <10000 9800 9600 9400 9200 9000>,
			<8800 8600 8400 8200 8000 7800>,
			<7600 7400 7200 7000 6800 6600>,
			<6400 6200 6000 5800 5600 5400>,
			<5200 5000 4800 4600 4400 4200>,
			<4000 3800 3600 3400 3200 3000>,
			<2800 2600 2400 2200 2000 1800>,
			<1600 1400 1200 1000 900 800>,
			<700 600 500 400 300 200>,
			<100 0>;
		qcom,lut-data = <16671 16589 16550 16484 16463 16470>,
			<16734 16616 16564 16485 16465 16472>,
			<16827 16667 16586 16485 16467 16475>,
			<16929 16724 16608 16485 16469 16479>,
			<17014 16772 16625 16485 16471 16481>,
			<17061 16792 16631 16485 16472 16482>,
			<17073 16795 16629 16485 16472 16482>,
			<17080 16796 16626 16484 16471 16482>,
			<17084 16794 16621 16484 16471 16481>,
			<17086 16785 16613 16484 16469 16480>,
			<17088 16780 16609 16484 16469 16479>,
			<17093 16785 16607 16486 16469 16478>,
			<17100 16794 16607 16489 16470 16478>,
			<17102 16807 16610 16493 16471 16478>,
			<17100 16831 16621 16498 16474 16478>,
			<17096 16854 16636 16505 16478 16479>,
			<17072 16878 16664 16515 16482 16480>,
			<17013 16895 16694 16528 16488 16483>,
			<16959 16882 16727 16553 16496 16487>,
			<16915 16828 16757 16584 16507 16495>,
			<16874 16773 16751 16605 16529 16513>,
			<16835 16724 16688 16621 16577 16558>,
			<16798 16679 16625 16627 16602 16582>,
			<16759 16647 16580 16568 16551 16541>,
			<16709 16623 16544 16489 16482 16484>,
			<16666 16603 16528 16473 16468 16472>,
			<16652 16588 16518 16468 16464 16469>,
			<16645 16572 16512 16467 16462 16468>,
			<16642 16548 16509 16469 16464 16469>,
			<16645 16519 16507 16472 16467 16469>,
			<16650 16509 16503 16475 16472 16472>,
			<16654 16512 16499 16479 16479 16480>,
			<16658 16516 16495 16484 16488 16490>,
			<16662 16525 16493 16491 16500 16509>,
			<16667 16542 16492 16495 16509 16522>,
			<16673 16556 16497 16494 16511 16522>,
			<16680 16573 16510 16492 16513 16521>,
			<16689 16591 16522 16488 16510 16517>,
			<16696 16606 16535 16479 16493 16505>,
			<16700 16618 16542 16473 16481 16497>,
			<16703 16620 16543 16476 16487 16505>,
			<16703 16619 16543 16480 16495 16514>,
			<16695 16617 16542 16484 16500 16517>,
			<16689 16616 16539 16476 16475 16485>,
			<16685 16607 16543 16451 16441 16445>,
			<16674 16598 16544 16464 16456 16470>,
			<16667 16606 16561 16481 16491 16515>,
			<16669 16615 16586 16507 16535 16561>,
			<16717 16626 16615 16548 16577 16605>,
			<16864 16740 16657 16581 16600 16619>,
			<17203 17270 16791 16551 16552 16556>,
			<18050 20082 18156 16518 16491 16496>,
			<21258 42033 34008 16533 16488 16493>,
			<20524 65535 65535 16574 16487 16488>,
			<20524 65535 65535 16574 16487 16488>,
			<20524 65535 65535 16574 16487 16488>;
	};

	qcom,pc-temp-y5-lut {
		qcom,lut-col-legend = <(-10) 0 10 25 40 50>;
		qcom,lut-row-legend = <10000 9800 9600 9400 9200 9000>,
			<8800 8600 8400 8200 8000 7800>,
			<7600 7400 7200 7000 6800 6600>,
			<6400 6200 6000 5800 5600 5400>,
			<5200 5000 4800 4600 4400 4200>,
			<4000 3800 3600 3400 3200 3000>,
			<2800 2600 2400 2200 2000 1800>,
			<1600 1400 1200 1000 900 800>,
			<700 600 500 400 300 200>,
			<100 0>;
		qcom,lut-data = <13442 18022 21038 21130 18414 19973>,
			<14338 18029 20801 21218 19264 20453>,
			<15221 18102 20512 21211 20434 21009>,
			<16044 18225 20231 21130 21618 21533>,
			<16760 18384 20025 20997 22509 21912>,
			<17322 18564 19955 20831 22810 22034>,
			<17759 18848 20002 20555 22721 21927>,
			<18103 19112 20056 20223 22534 21800>,
			<18283 19115 19993 19908 22108 21805>,
			<18373 18928 19742 19512 21268 21852>,
			<18470 18655 19443 19129 20733 21860>,
			<18700 18022 19083 18582 19960 21658>,
			<19114 17354 18637 18014 19326 21324>,
			<19651 17196 18003 17516 19357 20909>,
			<20617 17134 17204 16965 19436 20362>,
			<21450 17146 16633 16579 19160 19852>,
			<21679 18542 16166 16222 18003 19406>,
			<21805 20548 15935 15893 17036 18872>,
			<21867 21629 17031 15552 16751 17825>,
			<21200 22419 19325 15259 16580 16665>,
			<20397 22815 21085 16086 16597 16417>,
			<20147 22941 22607 20410 16895 16389>,
			<19588 23014 23691 23301 17423 16392>,
			<18923 23200 24388 23872 19826 18277>,
			<17410 23573 24878 24197 22585 21100>,
			<15563 23762 25025 24277 22735 22171>,
			<14557 23808 24838 24063 22041 22764>,
			<13812 23830 24703 23992 21239 22863>,
			<13451 23556 24506 24317 20130 20568>,
			<13343 22593 24392 24535 19180 17908>,
			<13281 21466 24846 24000 18893 17346>,
			<13301 19895 25697 23030 18732 17081>,
			<13459 18427 25946 22842 18761 17134>,
			<13638 17760 25713 23899 19574 18530>,
			<13841 17753 25350 25154 20832 20252>,
			<14071 17886 24756 26046 22791 21368>,
			<14174 17102 24045 26793 25044 22319>,
			<14220 16252 23928 27096 25480 23058>,
			<14264 16160 24126 27252 25219 23723>,
			<14406 16193 24254 27298 24874 24032>,
			<14586 16021 24003 25877 24376 23711>,
			<14574 15528 23585 24670 24088 23337>,
			<14339 15089 23270 24650 24905 23966>,
			<13977 14683 21791 25542 24621 23701>,
			<13299 14277 16222 24201 23900 24852>,
			<13440 13726 15505 22291 21401 18225>,
			<13236 13554 15138 22100 18227 15460>,
			<12956 13616 14923 21159 16321 14494>,
			<12343 13782 14746 19828 15533 14116>,
			<11346 12259 14379 18741 15135 14077>,
			<10412 10462 12902 19137 15486 14578>,
			<9794 9442 10285 19601 16442 15745>,
			<9556 9004 9021 19870 16559 14955>,
			<16402 8858 8818 20764 18682 17431>,
			<16402 8858 8818 20764 18682 17431>,
			<16402 8858 8818 20764 18682 17431>;
	};

	qcom,pc-temp-y6-lut {
		qcom,lut-col-legend = <(-10) 0 10 25 40 50>;
		qcom,lut-row-legend = <10000 9800 9600 9400 9200 9000>,
			<8800 8600 8400 8200 8000 7800>,
			<7600 7400 7200 7000 6800 6600>,
			<6400 6200 6000 5800 5600 5400>,
			<5200 5000 4800 4600 4400 4200>,
			<4000 3800 3600 3400 3200 3000>,
			<2800 2600 2400 2200 2000 1800>,
			<1600 1400 1200 1000 900 800>,
			<700 600 500 400 300 200>,
			<100 0>;
		qcom,lut-data = <5779 5359 5178 5045 5002 4993>,
			<5795 5369 5187 5046 5003 4995>,
			<5811 5379 5192 5046 5005 4997>,
			<5823 5388 5195 5046 5006 4998>,
			<5832 5395 5196 5046 5008 5000>,
			<5836 5397 5196 5046 5008 5001>,
			<5834 5396 5194 5045 5009 5001>,
			<5829 5393 5190 5045 5009 5002>,
			<5824 5389 5186 5045 5009 5002>,
			<5817 5384 5182 5045 5009 5002>,
			<5812 5379 5179 5045 5009 5002>,
			<5810 5375 5176 5045 5009 5002>,
			<5808 5373 5175 5046 5009 5003>,
			<5806 5373 5175 5047 5010 5003>,
			<5803 5374 5176 5049 5012 5004>,
			<5799 5376 5177 5051 5013 5004>,
			<5789 5382 5181 5054 5015 5005>,
			<5770 5389 5187 5059 5016 5007>,
			<5751 5384 5195 5066 5019 5008>,
			<5734 5365 5204 5073 5024 5011>,
			<5717 5346 5201 5079 5031 5016>,
			<5705 5329 5180 5084 5043 5028>,
			<5695 5315 5159 5086 5048 5035>,
			<5685 5306 5145 5066 5031 5019>,
			<5676 5299 5134 5041 5008 4999>,
			<5669 5294 5129 5036 5003 4995>,
			<5670 5292 5126 5034 5001 4995>,
			<5681 5289 5125 5034 5001 4994>,
			<5695 5286 5125 5035 5001 4994>,
			<5715 5284 5125 5036 5002 4993>,
			<5740 5283 5126 5038 5003 4994>,
			<5767 5290 5126 5039 5006 4996>,
			<5797 5302 5127 5040 5009 5000>,
			<5830 5317 5129 5043 5012 5006>,
			<5867 5337 5132 5045 5015 5011>,
			<5908 5360 5138 5045 5017 5011>,
			<5952 5386 5147 5045 5018 5010>,
			<5997 5415 5157 5044 5017 5009>,
			<6046 5450 5169 5043 5012 5006>,
			<6099 5489 5183 5041 5008 5003>,
			<6155 5531 5197 5043 5011 5007>,
			<6215 5576 5214 5045 5013 5010>,
			<6279 5631 5238 5047 5015 5010>,
			<6357 5701 5270 5046 5007 4999>,
			<6461 5799 5275 5039 4997 4989>,
			<6625 5934 5354 5047 5005 5000>,
			<6728 6071 5422 5056 5017 5014>,
			<6911 6285 5526 5066 5031 5029>,
			<7410 6663 5697 5080 5044 5043>,
			<8493 7711 6050 5091 5051 5048>,
			<10772 10780 6988 5082 5035 5028>,
			<16129 21114 10452 5075 5019 5013>,
			<30782 63718 26984 5093 5021 5015>,
			<65535 65535 65535 5132 5028 5021>,
			<65535 65535 65535 5132 5028 5021>,
			<65535 65535 65535 5132 5028 5021>;
	};

};
